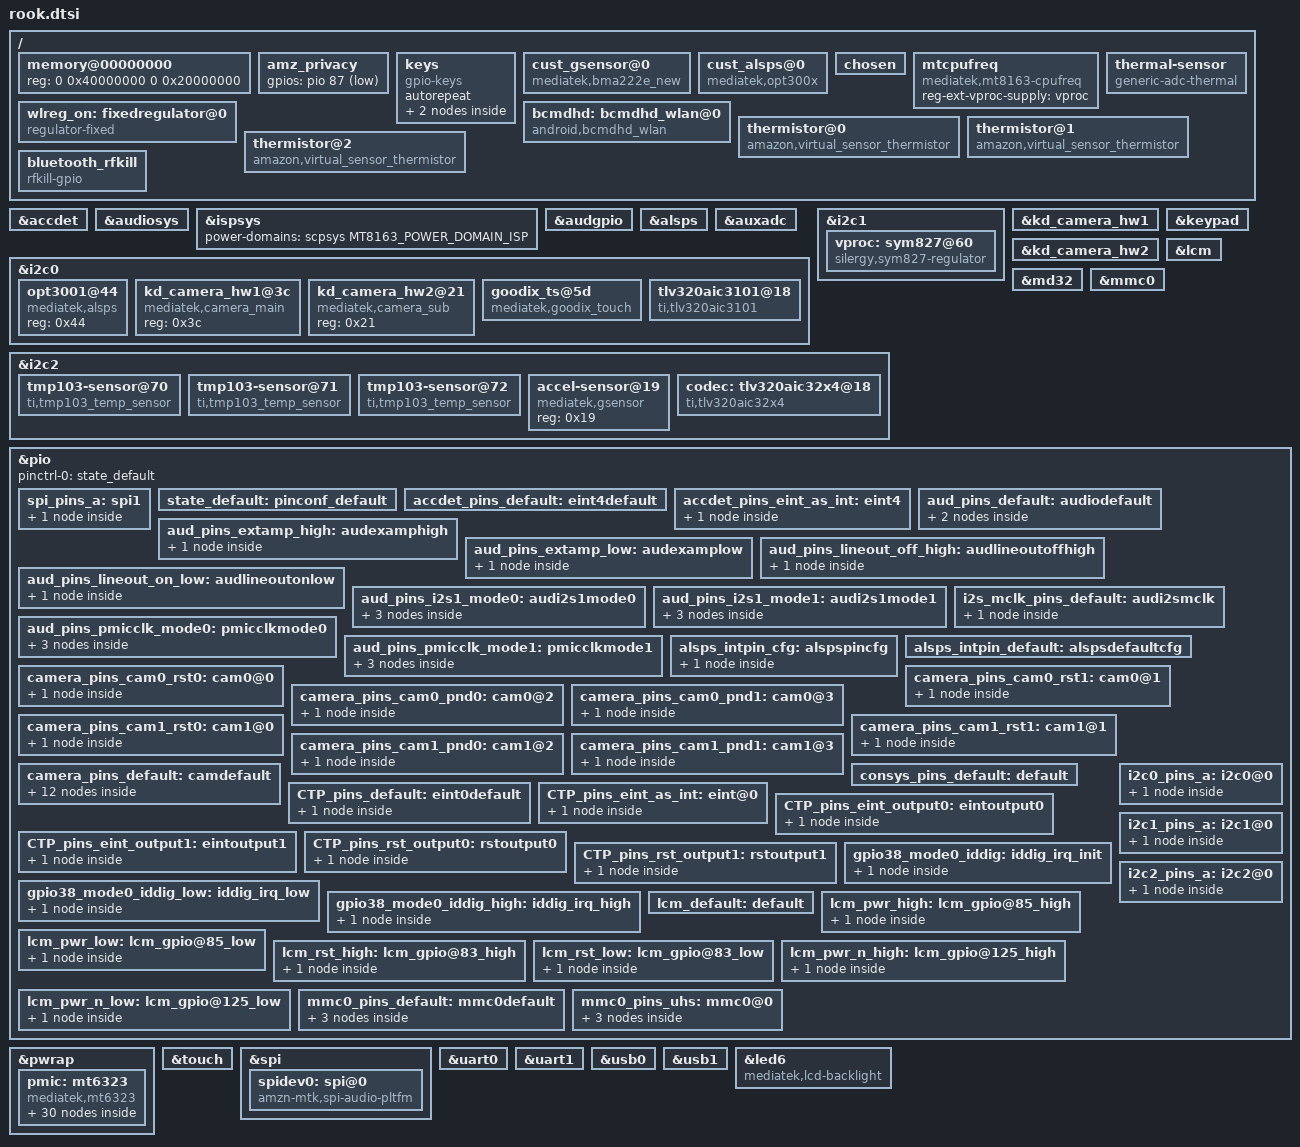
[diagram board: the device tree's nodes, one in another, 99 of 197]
/*
 * Copyright 2011-2017 Amazon.com, Inc. or its affiliates. All Rights Reserved.
 */

#include "mt8163.dtsi"

/ {
	memory@00000000 {
		device_type = "memory";
		reg = <0 0x40000000 0 0x20000000>;
	};

	amz_privacy {
		gpios = <&pio 87 1>;
	};

	keys {
		compatible = "gpio-keys";
		autorepeat;
		vol_up: volumeup@115 {
			label = "Volume Up Key";
			linux,code = <115>;
			gpios = <&pio 37 1>;
			debounce-interval = <20>;
		};
		vol_dn: volumedn@114 {
			label = "Volume Down Key";
			linux,code = <114>;
			gpios = <&pio 50 1>;
			debounce-interval = <20>;
		};
	};

	/* Accel Sensor */
	cust_gsensor@0 {
		compatible = "mediatek,bma222e_new";
		i2c_num = <2>;
		i2c_addr = <0x19>;
		direction = <0>;
		power_id = <0xffff>;
		power_vol = <0>;
		firlen = <0>;
		is_batch_supported = <0>;
	};

	cust_alsps@0 {
		compatible              = "mediatek,opt300x";
		i2c_num                 = <0>;
		i2c_addr                = <0x44>;
		polling_mode_als        = <1>;
		power_id                = <0xffff>;
		power_vol               = <0>;
		/* Total has 15 level*/
		als_level       = <0 257 637 1027 2297 5588 6730 11301 20449 25768 31122 45552 57937 57937 57937>;
		/*  Total has 16 range*/
		als_value       = <0 132 304 502 1004 2003 3006 5006 8004 10000 12000 16000 20000 20000 20000 20000>;
		is_batch_supported_ps   = <1>;
	};


	/* chosen */
	chosen {
		bootargs = "console=ttyMT0,921600n1 root=/dev/ram initrd=0x44000200,0x200000";
	};

	mtcpufreq {
		compatible = "mediatek,mt8163-cpufreq";
		reg-ext-vproc-supply = <&vproc>;
	};

	wlreg_on: fixedregulator@0 {
		compatible = "regulator-fixed";
		regulator-name = "wlreg_on";
		regulator-min-microvolt = <1800000>;
		regulator-max-microvolt = <1800000>;
		gpio = <&pio 27 0>;
		startup-delay-us = <1000>;
		enable-active-high;
	};

	bcmdhd: bcmdhd_wlan@0 {
		compatible = "android,bcmdhd_wlan";
		gpios = <&pio 29 0>;
		wlreg_on-supply = <&wlreg_on>;
	};

	/* auxadc thermistor channel */
	thermal-sensor {
		compatible = "generic-adc-thermal";
		#thermal-sensor-cells = <0>;
		io-channels = <&auxadc 0>, <&auxadc 14>, <&auxadc 15>, <&auxadc 12>;
		io-channel-names = "sensor-channel";
	};

	/* Virtual sensor thermistor */
	thermistor@0 {
		compatible = "amazon,virtual_sensor_thermistor";
		thermal_thermistor,offset = <13000>;
		thermal_thermistor,offset_invert = <1>;
		thermal_thermistor,alpha = <50>;
		thermal_thermistor,weight = <380>;
		aux_channel_num = <0>;
		select_device = <0>;
	};
	thermistor@1 {
		compatible = "amazon,virtual_sensor_thermistor";
		thermal_thermistor,offset = <63500>;
		thermal_thermistor,offset_invert = <1>;
		thermal_thermistor,alpha = <100>;
		thermal_thermistor,weight = <0>;
		aux_channel_num = <1>;
		select_device = <1>;
	};
	thermistor@2 {
		compatible = "amazon,virtual_sensor_thermistor";
		thermal_thermistor,offset = <14000>;
		thermal_thermistor,offset_invert = <1>;
		thermal_thermistor,alpha = <50>;
		thermal_thermistor,weight = <250>;
		aux_channel_num = <2>;
		select_device = <0>;
	};

	bluetooth_rfkill: bluetooth_rfkill {
		compatible = "rfkill-gpio";
		label = "bluetooth";
		radio-type = "bluetooth";
		shutdown-gpios = <&pio 28 0>;
		default-blocked;
	};
};

&accdet {
	interrupt-parent = <&pio>;
	interrupts = <4 IRQ_TYPE_LEVEL_HIGH>;
	eint-debounce = <512000>;
	accdet-gpio = <&pio 26 0>;
	accdet-plugout-debounce = <20000>;
	pinctrl-names = "default", "state_eint_as_int";
	pinctrl-0 = <&accdet_pins_default>;
	pinctrl-1 = <&accdet_pins_eint_as_int>;
	status = "okay";
};

&audiosys {
	/*0:Stereo, 1:MonoLeft, 2:MonoRight*/
	channel-type = <2>;
	/* MCLK Frequency for ADC3101/DAC3203 */
	mclk-frequency = <24576000>;
	interrupt-parent = <&pio>;
	interrupts = <4 IRQ_TYPE_LEVEL_LOW>;
	amp-fault-debounce = <512000>;
	amp-fault-gpio = <&pio 121 0>;
};

&ispsys {
	/* Power domains */
	power-domains = <&scpsys MT8163_POWER_DOMAIN_ISP>;
};

&audgpio {
	pinctrl-names = "default",
			"audpmicclk-mode0",
			"audpmicclk-mode1",
			"audi2s1-mode0",
			"audi2s1-mode1",
			"extamp-pullhigh",
			"extamp-pulllow",
			"i2s-mclk",
			"lineout-off-pullhigh",
			"lineout-on-pulllow";
	pinctrl-0 = <&aud_pins_default>;
	pinctrl-1 = <&aud_pins_pmicclk_mode0>;
	pinctrl-2 = <&aud_pins_pmicclk_mode1>;
	pinctrl-3 = <&aud_pins_i2s1_mode0>;
	pinctrl-4 = <&aud_pins_i2s1_mode1>;
	pinctrl-5 = <&aud_pins_extamp_high>;
	pinctrl-6 = <&aud_pins_extamp_low>;
	pinctrl-7 = <&i2s_mclk_pins_default>;
	pinctrl-8 = <&aud_pins_lineout_off_high>;
	pinctrl-9 = <&aud_pins_lineout_on_low>;

	clocks = <&infracfg CLK_INFRA_AUDIO>,
		 <&topckgen CLK_TOP_AUDIO_SEL>,
		 <&topckgen CLK_TOP_AUD_INTBUS_SEL>,
		 <&topckgen CLK_TOP_AUD_1_SEL>,
		 <&topckgen CLK_TOP_AUD_2_SEL>,
		 <&topckgen CLK_TOP_APLL1>,
		 <&topckgen CLK_TOP_APLL2>,
		 <&audiosys CLK_AUDIO_AFE>,
		 <&audiosys CLK_AUDIO_DAC>,
		 <&audiosys CLK_AUDIO_DAC_PREDIS>,
		 <&audiosys CLK_AUDIO_ADC>,
		 <&audiosys CLK_AUDIO_22M>,
		 <&audiosys CLK_AUDIO_24M>,
		 <&audiosys CLK_AUDIO_I2S>,
		 <&audiosys CLK_AUDIO_APLL_TUNER>,
		 <&audiosys CLK_AUDIO_APLL2_TUNER>,
		 <&clk26m>;

	clock-names = "aud_infra_clk",
		      "top_mux_audio",
		      "top_mux_audio_intbus",
		      "aud_mux1_clk",
		      "aud_mux2_clk",
		      "apll1_clk",
		      "apll2_clk",
		      "aud_afe",
		      "aud_dac",
		      "aud_dac_predis",
		      "aud_adc",
		      "aud_22m",
		      "aud_24m",
		      "aud_i2s",
		      "aud_apll_tnr",
		      "aud_apll2_tnr",
		      "top_clk26m_clk";

	status = "okay";
};

&alsps {
	pinctrl-names = "pin_default", "pin_cfg";
	pinctrl-0 = <&alsps_intpin_default>;
	pinctrl-1 = <&alsps_intpin_cfg>;
	status = "okay";
};

&auxadc {
	status = "okay";
};


&i2c0 {
	clock-frequency = <400000>;
	pinctrl-names = "default";
	pinctrl-0 = <&i2c0_pins_a>;
	status = "okay";
	clock-div = <10>;

	opt3001@44 {
		compatible = "mediatek,alsps";
		reg = <0x44>;
	};

	/* in cust_i2c_projXXX.dtsi ? */
	kd_camera_hw1@3c { /* Fix me to right reg val */
		compatible = "mediatek,camera_main";
		reg = <0x3c>;
	};

	/* in cust_i2c_projXXX.dtsi ? */
	kd_camera_hw2@21 { /* Fix me to right reg val */
		compatible = "mediatek,camera_sub";
		reg = <0x21>;
	};

	goodix_ts@5d {
		compatible = "mediatek,goodix_touch";
		reg = <0x5d>;
		interrupt-parent = <&pio>;
		interrupts = <17 IRQ_TYPE_EDGE_RISING>;
	};

	tlv320aic3101@18 {
		compatible = "ti,tlv320aic3101";
		reg = <0x18>, <0x1a>;
		reg-names = "adc0", "adc1";
		enable-gpio = <&pio 35 0>;
		clocks = <&clk26m>;
		clock-names = "mclk";
	};

};

&i2c1 {
	clock-frequency = <400000>;
	pinctrl-names = "default";
	pinctrl-0 = <&i2c1_pins_a>;
	status = "okay";
	clock-div = <10>;

	vproc: sym827@60 {
		compatible = "silergy,sym827-regulator";
		reg = <0x60>;
		regulator-name = "vproc";
		regulator-min-microvolt = <600000>;
		regulator-max-microvolt = <1387500>;
		regulator-enable-ramp-delay = <400>;
		regulator-ramp-delay = <8333>;
		regulator-always-on;
		vsel-gpio = <&pio 34 0>;
	};
};

&i2c2 {
	clock-frequency = <400000>;
	pinctrl-names = "default";
	pinctrl-0 = <&i2c2_pins_a>;
	status = "okay";
	clock-div = <10>;

	tmp103-sensor@70 {
		compatible = "ti,tmp103_temp_sensor";
		reg = <0x70>;
		tmp103-sensor,offset = <2300>;
		tmp103-sensor,alpha = <10>;
		tmp103-sensor,weight = <0>;
	};
	tmp103-sensor@71 {
		compatible = "ti,tmp103_temp_sensor";
		reg = <0x71>;
		tmp103-sensor,offset = <750>;
		tmp103-sensor,alpha = <10>;
		tmp103-sensor,weight = <0>;
	};
	tmp103-sensor@72 {
		compatible = "ti,tmp103_temp_sensor";
		reg = <0x72>;
		tmp103-sensor,offset = <750>;
		tmp103-sensor,alpha = <10>;
		tmp103-sensor,weight = <0>;
	};

	accel-sensor@19 {
		compatible = "mediatek,gsensor";
		reg = <0x19>;
	};


	codec: tlv320aic32x4@18 {
		compatible = "ti,tlv320aic32x4";
		reg = <0x18>;
		reset-gpios = <&pio 22 0>;
		clocks = <&clk26m>;
		clock-names = "mclk";
	};
};

/* Main Cam */
&kd_camera_hw1 {
	reg-vcama-supply = <&mt6323_vcama_reg>;		/* AVDD */
	reg-vcamd-supply = <&mt6323_vcamd_reg>;		/* DVDD */
	reg-vcamio-supply = <&mt6323_vcamio_reg>;	/* DOVDD */
	reg-vcami2c-supply = <&mt6323_vio18_reg>;	/* I2C */

	pinctrl-names = "default", "cam0_rst0", "cam0_rst1", "cam0_pnd0", "cam0_pnd1",
			"cam1_rst0", "cam1_rst1", "cam1_pnd0", "cam1_pnd1","cam_ldo0_0", "cam_ldo0_1";
	pinctrl-0 = <&camera_pins_default>;
	pinctrl-1 = <&camera_pins_cam0_rst0>;
	pinctrl-2 = <&camera_pins_cam0_rst1>;
	pinctrl-3 = <&camera_pins_cam0_pnd0>;
	pinctrl-4 = <&camera_pins_cam0_pnd1>;
	pinctrl-5 = <&camera_pins_cam1_rst0>;
	pinctrl-6 = <&camera_pins_cam1_rst1>;
	pinctrl-7 = <&camera_pins_cam1_pnd0>;
	pinctrl-8 = <&camera_pins_cam1_pnd1>;
/*
	pinctrl-9 = <&camera_pins_cam_ldo0_0>;
	pinctrl-10 = <&camera_pins_cam_ldo0_1>;
*/
	status = "okay";

};

/* Sub Cam */
/* FIX ME: same power pins as Main ? */
&kd_camera_hw2{
	reg-vcama-supply = <&mt6323_vcama_reg>;		/* AVDD */
	reg-vcamd-supply = <&mt6323_vcamd_reg>;		/* DVDD */
	reg-vcamio-supply = <&mt6323_vcamio_reg>;	/* DOVDD */
	reg-vcami2c-supply = <&mt6323_vio18_reg>;	/* I2C */
};

&keypad {
	mediatek,kpd-key-debounce = <1024>;
	mediatek,kpd-sw-pwrkey = <116>;
	mediatek,kpd-hw-pwrkey = <8>;
	mediatek,kpd-sw-rstkey  = <114>;
	mediatek,kpd-hw-rstkey = <17>;
	mediatek,kpd-use-extend-type = <0>;
	/*HW Keycode [0~71] -> Linux Keycode*/
	mediatek,kpd-hw-map-num = <72>;
	mediatek,kpd-hw-init-map = <138 0 0 0 0 0 0 0 0 0 0 0 0 0 0 0 0 0 0 0 0 0 0 0
			0 0 0 0 0 0 0 0 0 0 0 0 0 0 0 0 0 0 0 0 0 0 0 0
			0 0 0 0 0 0 0 0 0 0 0 0 0 0 0 0 0 0 0 0 0 0 0 0 >;
	mediatek,kpd-pwrkey-eint-gpio = <0>;
	mediatek,kpd-pwkey-gpio-din  = <0>;
	mediatek,kpd-hw-dl-key0 = <0>;
	mediatek,kpd-hw-dl-key1 = <17>;
	mediatek,kpd-hw-dl-key2 = <8>;
	mediatek,kpd-hw-recovery-key = <0>;
	mediatek,kpd-hw-factory-key  = <17>;
	mediatek,kpd-show-hw-keycode = <0>;
};

&lcm {
	pinctrl-names = "default", "lcm_pwr_high", "lcm_pwr_low", "lcm_rst_high", "lcm_rst_low",
			"lcm_pwr_n_high", "lcm_pwr_n_low";
	pinctrl-0 = <&lcm_default>;
	pinctrl-1 = <&lcm_pwr_high>;
	pinctrl-2 = <&lcm_pwr_low>;
	pinctrl-3 = <&lcm_rst_high>;
	pinctrl-4 = <&lcm_rst_low>;
	pinctrl-5 = <&lcm_pwr_n_high>;
	pinctrl-6 = <&lcm_pwr_n_low>;
	lcm-vcn33-supply = <&mt6323_vcn33_wifi_reg>;
	lcm-vmch-supply = <&mt6323_vmch_reg>;
	panelid0-gpio = <&pio 32 0>;
	panelid1-gpio = <&pio 44 0>;
};

&md32 {
	status = "okay";
};

&mmc0 {
	pinctrl-names = "default", "state_uhs";
	pinctrl-0 = <&mmc0_pins_default>;
	pinctrl-1 = <&mmc0_pins_uhs>;
	status = "okay";
	bus-width = <8>;
	mediatek,latch-ck = <1>;
	max-frequency = <200000000>;
	cap-mmc-highspeed;
	mmc-hs200-1_8v;
	cap-mmc-hw-reset;
	vmmc-supply = <&mt6323_vemc3v3_reg>;
	vqmmc-supply = <&mt6323_vio18_reg>;
	non-removable;
};

&pio {
	pinctrl-names = "default";
	pinctrl-0 = <&state_default>;

	spi_pins_a: spi1 {
		spi_pads: pins_spi {
			drive-strength = <MTK_DRIVE_4mA>;
		};
	};

	state_default:pinconf_default {
	};

	accdet_pins_default: eint4default {
	};

	accdet_pins_eint_as_int: eint4 {
		pins_cmd_dat {
			pinmux = <MT8163_PIN_26_EINT4__FUNC_GPIO26>;
			bias-disable;
		};
	};

	aud_pins_default: audiodefault {
		pins1 {
			pinmux = <MT8163_PIN_18_PCM_CLK__FUNC_I2S0_BCK0>,
			<MT8163_PIN_19_PCM_SYNC__FUNC_I2S0_LRCK>,
			<MT8163_PIN_20_PCM_RX__FUNC_I2S0_DI>,
			<MT8163_PIN_21_PCM_TX__FUNC_I2S3_DO>;
		};
		pins_cmd_dat {
			pinmux = <MT8163_PIN_121_MSDC1_CMD__FUNC_GPIO121>;
			bias-pull-up = <MTK_PUPD_SET_R1R0_01>;
			drive-strength = <MTK_DRIVE_2mA>;
			input-enable;
		};
	};

	aud_pins_extamp_high: audexamphigh {
		pins_cmd_dat {
			pinmux = <MT8163_PIN_122_MSDC1_CLK__FUNC_GPIO122>;
			slew-rate = <1>;
			output-high;
		};
	};

	aud_pins_extamp_low: audexamplow {
		pins_cmd_dat {
			pinmux = <MT8163_PIN_122_MSDC1_CLK__FUNC_GPIO122>;
			slew-rate = <1>;
			output-low;
		};
	};

	aud_pins_lineout_off_high: audlineoutoffhigh {
		pins_cmd_dat {
			pinmux = <MT8163_PIN_124_MSDC1_DAT1__FUNC_GPIO124>;
			slew-rate = <1>;
			output-high;
		};
	};

	aud_pins_lineout_on_low: audlineoutonlow {
		pins_cmd_dat {
			pinmux = <MT8163_PIN_124_MSDC1_DAT1__FUNC_GPIO124>;
			slew-rate = <1>;
			output-low;
		};
	};


	aud_pins_i2s1_mode0: audi2s1mode0 {
		pins_cmd0_dat {
			pinmux = <MT8163_PIN_72_I2S_DATA_IN__FUNC_GPIO72>;
		};
		pins_cmd1_dat {
			pinmux = <MT8163_PIN_73_I2S_LRCK__FUNC_GPIO73>;
		};
		pins_cmd2_dat {
			pinmux = <MT8163_PIN_74_I2S_BCK__FUNC_GPIO74>;
		};
	};

	aud_pins_i2s1_mode1: audi2s1mode1 {
		pins_cmd0_dat {
			pinmux = <MT8163_PIN_72_I2S_DATA_IN__FUNC_I2S1_DO>;
			drive-strength = <MTK_DRIVE_8mA>;
		};
		pins_cmd1_dat {
			pinmux = <MT8163_PIN_73_I2S_LRCK__FUNC_I2S1_LRCK>;
			drive-strength = <MTK_DRIVE_8mA>;
		};
		pins_cmd2_dat {
			pinmux = <MT8163_PIN_74_I2S_BCK__FUNC_I2S1_BCK>;
			drive-strength = <MTK_DRIVE_8mA>;
		};
	};

	i2s_mclk_pins_default: audi2smclk {
		pins_i2s3_mck {
			pinmux = <MT8163_PIN_6_PWRAP_SPI0_CSN2__FUNC_I2S2_MCK>;
		};
	};

	aud_pins_pmicclk_mode0: pmicclkmode0 {
		pins_cmd0_dat {
			pinmux = <MT8163_PIN_7_AUD_CLK_MOSI__FUNC_GPIO7>;
		};
		pins_cmd1_dat {
			pinmux = <MT8163_PIN_8_AUD_DAT_MISO__FUNC_GPIO8>;
		};
		pins_cmd2_dat {
			pinmux = <MT8163_PIN_9_AUD_DAT_MOSI__FUNC_GPIO9>;
		};
	};

	aud_pins_pmicclk_mode1: pmicclkmode1 {
		pins_cmd0_dat {
			pinmux = <MT8163_PIN_7_AUD_CLK_MOSI__FUNC_AUD_CLK_MOSI>;
		};
		pins_cmd1_dat {
			pinmux = <MT8163_PIN_8_AUD_DAT_MISO__FUNC_AUD_DAT_MISO>;
		};
		pins_cmd2_dat {
			pinmux = <MT8163_PIN_9_AUD_DAT_MOSI__FUNC_AUD_DAT_MOSI>;
		};
	};

	alsps_intpin_cfg: alspspincfg {
		pins_cmd_dat {
			pinmux = <MT8163_PIN_23_EINT1__FUNC_GPIO23>;
			slew-rate = <0>;
			bias-pull-up = <00>;
		};
	};

	alsps_intpin_default: alspsdefaultcfg {
	};


	/* CAMERA GPIO standardization */
	/* Project Dependency : tb8163m1 */
	camera_pins_cam0_rst0: cam0@0 {
		pins_cmd_dat {
			pinmux = <MT8163_PIN_53_SPI_CS__FUNC_GPIO53>;/*GPIO_CAMERA_CMRST_PIN*/
			slew-rate = <1>; /*direction 0:in, 1:out*/
			output-low;/*direction out used only. output_low or high*/
		};
	};
	camera_pins_cam0_rst1: cam0@1 {
		pins_cmd_dat {
			pinmux = <MT8163_PIN_53_SPI_CS__FUNC_GPIO53>;/*GPIO_CAMERA_CMRST_PIN*/
			slew-rate = <1>;
			output-high;
		};
	};
	camera_pins_cam0_pnd0: cam0@2 {
		pins_cmd_dat {
			pinmux = <MT8163_PIN_56_SPI_MO__FUNC_GPIO56>;/*GPIO_CAMERA_CMPDN_PIN*/
			slew-rate = <1>;
			output-low;
		};
	};
	camera_pins_cam0_pnd1: cam0@3 {
		pins_cmd_dat {
			pinmux = <MT8163_PIN_56_SPI_MO__FUNC_GPIO56>;/*GPIO_CAMERA_CMPDN_PIN*/
			slew-rate = <1>;
			output-high;
		};
	};
	camera_pins_cam1_rst0: cam1@0 {
		pins_cmd_dat {
			pinmux = <MT8163_PIN_55_SPI_MI__FUNC_GPIO55>;/*GPIO_CAMERA_CMRST1_PIN*/
			slew-rate = <1>; /*direction 0:in, 1:out*/
			output-low;/*direction out used only. output_low or high*/
		};
	};
	camera_pins_cam1_rst1: cam1@1 {
		pins_cmd_dat {
			pinmux = <MT8163_PIN_55_SPI_MI__FUNC_GPIO55>;/*GPIO_CAMERA_CMRST1_PIN*/
			slew-rate = <1>;
			output-high;
		};
	};
	camera_pins_cam1_pnd0: cam1@2 {
		pins_cmd_dat {
			pinmux = <MT8163_PIN_90_MSDC2_DAT3__FUNC_GPIO90>;
			/*GPIO_CAMERA_CMPDN1_PIN*/
			slew-rate = <1>;
			output-low;
		};
	};
	camera_pins_cam1_pnd1: cam1@3 {
		pins_cmd_dat {
			pinmux = <MT8163_PIN_90_MSDC2_DAT3__FUNC_GPIO90>;
			/*GPIO_CAMERA_CMPDN1_PIN*/
			slew-rate = <1>;
			output-high;
		};
	};

/*
	camera_pins_cam_ldo0_0: cam@0 {
		pins_cmd_dat {
			pinmux = <PINMUX_GPIO68__FUNC_GPIO68>;
			slew-rate = <1>;
			output-low;
		};
	};
	camera_pins_cam_ldo0_1: cam@1 {
		pins_cmd_dat {
			pinmux = <PINMUX_GPIO68__FUNC_GPIO68>;
			slew-rate = <1>;
			output-high;
		};
	};
*/

	/* Set MCLK Pin default mode */
	camera_pins_default: camdefault {
		pins_cmd0_dat {
			pinmux = <MT8163_PIN_119_CMMCLK__FUNC_CMMCLK>;	/*MCLK*/
		};
		pins_cmd1_dat {
			pinmux = <MT8163_PIN_107_RDN2__FUNC_CMDAT8>;
		};
		pins_cmd2_dat {
			pinmux = <MT8163_PIN_108_RDP2__FUNC_CMDAT9>;
		};
		pins_cmd3_dat {
			pinmux = <MT8163_PIN_109_RDN3__FUNC_CMDAT4>;
		};
		pins_cmd4_dat {
			pinmux = <MT8163_PIN_110_RDP3__FUNC_CMDAT5>;
		};
		pins_cmd5_dat {
			pinmux = <MT8163_PIN_111_RCN_A__FUNC_CMDAT6>;
		};
		pins_cmd6_dat {
			pinmux = <MT8163_PIN_112_RCP_A__FUNC_CMDAT7>;
		};
		pins_cmd7_dat {
			pinmux = <MT8163_PIN_113_RDN1_A__FUNC_CMDAT2>;
		};
		pins_cmd8_dat {
			pinmux = <MT8163_PIN_114_RDP1_A__FUNC_CMDAT3>;
		};
		pins_cmd9_dat {
			pinmux = <MT8163_PIN_115_RDN0_A__FUNC_CMHSYNC>;
		};
		pins_cmd10_dat {
			pinmux = <MT8163_PIN_116_RDP0_A__FUNC_CMVSYNC>;
		};
		pins_cmd11_dat {
			pinmux = <MT8163_PIN_120_CMPCLK__FUNC_CMPCLK>;
		};
	};

	/* CONSYS GPIO Settings - Start */
	consys_pins_default: default {

	};
	/* CONSYS GPIO Settings - End */

	CTP_pins_default: eint0default {
		pins_cmd_dat {
			pinmux = <MT8163_PIN_49_EINT17__FUNC_GPIO49>;
			slew-rate = <0>;
			bias-disable;
		};
	};

	CTP_pins_eint_as_int: eint@0 {
		pins_cmd_dat {
			pinmux = <MT8163_PIN_49_EINT17__FUNC_GPIO49>;
			slew-rate = <0>;
			bias-pull-up;
		};
	};

	CTP_pins_eint_output0: eintoutput0 {
		pins_cmd_dat {
			pinmux = <MT8163_PIN_49_EINT17__FUNC_GPIO49>;
			slew-rate = <1>;
			output-low;
		};
	};

	CTP_pins_eint_output1: eintoutput1 {
		pins_cmd_dat {
			pinmux = <MT8163_PIN_49_EINT17__FUNC_GPIO49>;
			slew-rate = <1>;
			output-high;
		};
	};

	CTP_pins_rst_output0: rstoutput0 {
		pins_cmd_dat {
			pinmux = <MT8163_PIN_89_MSDC2_DAT2__FUNC_GPIO89>;
			slew-rate = <1>;
			output-low;
		};
	};

	CTP_pins_rst_output1: rstoutput1 {
		pins_cmd_dat {
			pinmux = <MT8163_PIN_89_MSDC2_DAT2__FUNC_GPIO89>;
			slew-rate = <1>;
			output-high;
		};
	};

/* USB GPIO start */
	gpio38_mode0_iddig: iddig_irq_init {
		pins_cmd_dat {
			pinmux = <MT8163_PIN_38_KPCOL2__FUNC_GPIO38>;
			bias-pull-up;
		};
	};

	gpio38_mode0_iddig_low: iddig_irq_low {
		pins_cmd_dat {
			pinmux = <MT8163_PIN_38_KPCOL2__FUNC_GPIO38>;
			bias-pull-down;
		};
	};

	gpio38_mode0_iddig_high: iddig_irq_high {
		pins_cmd_dat {
			pinmux = <MT8163_PIN_38_KPCOL2__FUNC_GPIO38>;
			bias-pull-up;
		};
	};

/* USB GPIO end */

	i2c0_pins_a: i2c0@0 {
		pins1 {
			pinmux = <MT8163_PIN_75_SDA0__FUNC_SDA0_0>,
				 <MT8163_PIN_76_SCL0__FUNC_SCL0_0>;
			bias-disable;
		};
	};

	i2c1_pins_a: i2c1@0 {
		pins1 {
			pinmux = <MT8163_PIN_57_SDA1__FUNC_SDA1_0>,
				 <MT8163_PIN_58_SCL1__FUNC_SCL1_0>;
			bias-disable;
		};
	};

	i2c2_pins_a: i2c2@0 {
		pins1 {
			pinmux = <MT8163_PIN_77_SDA2__FUNC_SDA2_0>,
				 <MT8163_PIN_78_SCL2__FUNC_SCL2_0>;
			bias-disable;
		};
	};

	lcm_default: default {
	};

	lcm_pwr_high: lcm_gpio@85_high {
		pins_cmd_dat {
			pinmux = <MT8163_PIN_85_MSDC2_CMD__FUNC_GPIO85>;
			slew-rate = <1>;
			output-high;
		};
	};

	lcm_pwr_low: lcm_gpio@85_low {
		pins_cmd_dat {
			pinmux = <MT8163_PIN_85_MSDC2_CMD__FUNC_GPIO85>;
			slew-rate = <1>;
			output-low;
		};
	};

	lcm_rst_high: lcm_gpio@83_high {
		pins_cmd_dat {
			pinmux = <MT8163_PIN_83_LCM_RST__FUNC_GPIO83>;
			slew-rate = <1>;
			output-high;
		};
	};

	lcm_rst_low: lcm_gpio@83_low {
		pins_cmd_dat {
			pinmux = <MT8163_PIN_83_LCM_RST__FUNC_GPIO83>;
			slew-rate = <1>;
			output-low;
		};
	};

	lcm_pwr_n_high: lcm_gpio@125_high {
		pins_cmd_dat {
			pinmux = <MT8163_PIN_125_MSDC1_DAT2__FUNC_GPIO125>;
			slew-rate = <1>;
			output-high;
		};
	};

	lcm_pwr_n_low: lcm_gpio@125_low {
		pins_cmd_dat {
			pinmux = <MT8163_PIN_125_MSDC1_DAT2__FUNC_GPIO125>;
			slew-rate = <1>;
			output-low;
		};
	};

	mmc0_pins_default: mmc0default {
		pins_cmd_dat {
			pinmux = <MT8163_PIN_137_MSDC0_DAT0__FUNC_MSDC0_DAT0>,
				<MT8163_PIN_136_MSDC0_DAT1__FUNC_MSDC0_DAT1>,
				<MT8163_PIN_135_MSDC0_DAT2__FUNC_MSDC0_DAT2>,
				<MT8163_PIN_134_MSDC0_DAT3__FUNC_MSDC0_DAT3>,
				<MT8163_PIN_130_MSDC0_DAT4__FUNC_MSDC0_DAT4>,
				<MT8163_PIN_129_MSDC0_DAT5__FUNC_MSDC0_DAT5>,
				<MT8163_PIN_128_MSDC0_DAT6__FUNC_MSDC0_DAT6>,
				<MT8163_PIN_127_MSDC0_DAT7__FUNC_MSDC0_DAT7>,
				<MT8163_PIN_132_MSDC0_CMD__FUNC_MSDC0_CMD>;
			input-enable;
			bias-pull-up;
		};

		pins_clk {
			pinmux = <MT8163_PIN_133_MSDC0_CLK__FUNC_MSDC0_CLK>;
			bias-pull-down;
		};

		pins_rst {
			pinmux = <MT8163_PIN_131_MSDC0_RSTB__FUNC_MSDC0_RSTB>;
			bias-pull-up;
		};
	};

	mmc0_pins_uhs: mmc0@0{
		pins_cmd_dat {
			pinmux = <MT8163_PIN_137_MSDC0_DAT0__FUNC_MSDC0_DAT0>,
				<MT8163_PIN_136_MSDC0_DAT1__FUNC_MSDC0_DAT1>,
				<MT8163_PIN_135_MSDC0_DAT2__FUNC_MSDC0_DAT2>,
				<MT8163_PIN_134_MSDC0_DAT3__FUNC_MSDC0_DAT3>,
				<MT8163_PIN_130_MSDC0_DAT4__FUNC_MSDC0_DAT4>,
				<MT8163_PIN_129_MSDC0_DAT5__FUNC_MSDC0_DAT5>,
				<MT8163_PIN_128_MSDC0_DAT6__FUNC_MSDC0_DAT6>,
				<MT8163_PIN_127_MSDC0_DAT7__FUNC_MSDC0_DAT7>,
				<MT8163_PIN_132_MSDC0_CMD__FUNC_MSDC0_CMD>;
			input-enable;
			drive-strength = <MTK_DRIVE_6mA>;
			bias-pull-up = <MTK_PUPD_SET_R1R0_01>;
		};

		pins_clk {
			pinmux = <MT8163_PIN_133_MSDC0_CLK__FUNC_MSDC0_CLK>;
			drive-strength = <MTK_DRIVE_6mA>;
			bias-pull-down = <MTK_PUPD_SET_R1R0_01>;
		};

		pins_rst {
			pinmux = <MT8163_PIN_131_MSDC0_RSTB__FUNC_MSDC0_RSTB>;
			bias-pull-up;
		};
	};

};

&pwrap {
	pmic: mt6323 {
		compatible = "mediatek,mt6323";

		pmicmt6323: pmicmt6323 {
			compatible = "mediatek,mt6323-pmic";
			interrupt-parent = <&pio>;
			interrupts = <24 IRQ_TYPE_LEVEL_HIGH>;
			/* 20s press to shutdown */
			long-press-shutdown-time = <8>;
		};

		regulators {

			compatible = "mediatek,mt6323-regulator";

			mt6323_vproc_reg: buck_vproc {
				regulator-name = "vproc";
				regulator-min-microvolt = < 700000>;
				regulator-max-microvolt = <1350000>;
				regulator-ramp-delay = <12500>;
				regulator-always-on;
				regulator-boot-on;
			};

			mt6323_vsys_reg: buck_vsys {
				regulator-name = "vsys";
				regulator-min-microvolt = <1400000>;
				regulator-max-microvolt = <2987500>;
				regulator-ramp-delay = <25000>;
				regulator-always-on;
				regulator-boot-on;
			};

			mt6323_vpa_reg: buck_vpa {
				regulator-name = "vpa";
				regulator-min-microvolt = < 500000>;
				regulator-max-microvolt = <3650000>;
			};

			mt6323_vtcxo_reg: ldo_vtcxo {
				regulator-name = "vtcxo";
				regulator-min-microvolt = <2800000>;
				regulator-max-microvolt = <2800000>;
				regulator-enable-ramp-delay = <90>;
				regulator-always-on;
				regulator-boot-on;
			};

			mt6323_vcn28_reg: ldo_vcn28 {
				regulator-name = "vcn28";
				regulator-min-microvolt = <2800000>;
				regulator-max-microvolt = <2800000>;
				regulator-enable-ramp-delay = <185>;
			};

			mt6323_vcn33_bt_reg: ldo_vcn33_bt {
				regulator-name = "vcn33_bt";
				regulator-min-microvolt = <3300000>;
				regulator-max-microvolt = <3600000>;
				regulator-enable-ramp-delay = <185>;
			};

			mt6323_vcn33_wifi_reg: ldo_vcn33_wifi {
				regulator-name = "vcn33_wifi";
				regulator-min-microvolt = <3300000>;
				regulator-max-microvolt = <3600000>;
				regulator-enable-ramp-delay = <185>;
				regulator-always-on;
				regulator-boot-on;
			};

			mt6323_va_reg: ldo_va {
				regulator-name = "va";
				regulator-min-microvolt = <2800000>;
				regulator-max-microvolt = <2800000>;
				regulator-enable-ramp-delay = <216>;
				regulator-always-on;
				regulator-boot-on;
			};

			mt6323_vcama_reg: ldo_vcama {
				regulator-name = "vcama";
				regulator-min-microvolt = <1500000>;
				regulator-max-microvolt = <2800000>;
				regulator-enable-ramp-delay = <216>;
			};

			mt6323_vio28_reg: ldo_vio28 {
				regulator-name = "vio28";
				regulator-min-microvolt = <2800000>;
				regulator-max-microvolt = <2800000>;
				regulator-enable-ramp-delay = <216>;
				regulator-always-on;
				regulator-boot-on;
			};

			mt6323_vusb_reg: ldo_vusb {
				regulator-name = "vusb";
				regulator-min-microvolt = <3300000>;
				regulator-max-microvolt = <3300000>;
				regulator-enable-ramp-delay = <216>;
				regulator-boot-on;
			};

			mt6323_vmc_reg: ldo_vmc {
				regulator-name = "vmc";
				regulator-min-microvolt = <1800000>;
				regulator-max-microvolt = <3300000>;
				regulator-enable-ramp-delay = <36>;
				regulator-boot-on;
			};

			mt6323_vmch_reg: ldo_vmch {
				regulator-name = "vmch";
				regulator-min-microvolt = <3000000>;
				regulator-max-microvolt = <3300000>;
				regulator-enable-ramp-delay = <36>;
				regulator-always-on;
				regulator-boot-on;
			};

			mt6323_vemc3v3_reg: ldo_vemc3v3 {
				regulator-name = "vemc3v3";
				regulator-min-microvolt = <3000000>;
				regulator-max-microvolt = <3300000>;
				regulator-enable-ramp-delay = <36>;
				regulator-boot-on;
			};

			mt6323_vgp1_reg: ldo_vgp1 {
				regulator-name = "vgp1";
				regulator-min-microvolt = <2800000>;
				regulator-max-microvolt = <3300000>;
				regulator-enable-ramp-delay = <216>;
				regulator-always-on;
				regulator-boot-on;
			};

			mt6323_vgp2_reg: ldo_vgp2 {
				regulator-name = "vgp2";
				regulator-min-microvolt = <1200000>;
				regulator-max-microvolt = <1200000>;
				regulator-enable-ramp-delay = <216>;
				regulator-always-on;
				regulator-boot-on;
			};

			mt6323_vgp3_reg: ldo_vgp3 {
				regulator-name = "vgp3";
				regulator-min-microvolt = <1800000>;
				regulator-max-microvolt = <1800000>;
				regulator-enable-ramp-delay = <216>;
			};

			mt6323_vcn18_reg: ldo_vcn18 {
				regulator-name = "vcn18";
				regulator-min-microvolt = <1800000>;
				regulator-max-microvolt = <1800000>;
				regulator-enable-ramp-delay = <216>;
			};

			mt6323_vsim1_reg: ldo_vsim1 {
				regulator-name = "vsim1";
				regulator-min-microvolt = <1800000>;
				regulator-max-microvolt = <3000000>;
				regulator-enable-ramp-delay = <216>;
			};

			mt6323_vsim2_reg: ldo_vsim2 {
				regulator-name = "vsim2";
				regulator-min-microvolt = <1800000>;
				regulator-max-microvolt = <3000000>;
				regulator-enable-ramp-delay = <216>;
			};

			mt6323_vrtc_reg: ldo_vrtc {
				regulator-name = "vrtc";
				regulator-min-microvolt = <2800000>;
				regulator-max-microvolt = <2800000>;
				regulator-always-on;
				regulator-boot-on;
			};

			mt6323_vcamaf_reg: ldo_vcamaf {
				regulator-name = "vcamaf";
				regulator-min-microvolt = <1800000>;
				regulator-max-microvolt = <1800000>;
				regulator-enable-ramp-delay = <216>;
			};

			mt6323_vibr_reg: ldo_vibr {
				regulator-name = "vibr";
				regulator-min-microvolt = <1200000>;
				regulator-max-microvolt = <3300000>;
				regulator-enable-ramp-delay = <36>;
			};

			mt6323_vrf18_reg: ldo_vrf18 {
				regulator-name = "vrf18";
				regulator-min-microvolt = <1825000>;
				regulator-max-microvolt = <1825000>;
				regulator-enable-ramp-delay = <187>;
				regulator-boot-on;
			};

			mt6323_vm_reg: ldo_vm {
				regulator-name = "vm";
				regulator-min-microvolt = <1200000>;
				regulator-max-microvolt = <1800000>;
				regulator-enable-ramp-delay = <216>;
				regulator-always-on;
				regulator-boot-on;
			};

			mt6323_vio18_reg: ldo_vio18 {
				regulator-name = "vio18";
				regulator-min-microvolt = <1800000>;
				regulator-max-microvolt = <1800000>;
				regulator-enable-ramp-delay = <216>;
				regulator-always-on;
				regulator-boot-on;
			};

			mt6323_vcamd_reg: ldo_vcamd {
				regulator-name = "vcamd";
				regulator-min-microvolt = <1200000>;
				regulator-max-microvolt = <1800000>;
				regulator-enable-ramp-delay = <216>;
			};

			mt6323_vcamio_reg: ldo_vcamio {
				regulator-name = "vcamio";
				regulator-min-microvolt = <1800000>;
				regulator-max-microvolt = <1800000>;
				regulator-enable-ramp-delay = <216>;
				regulator-always-on;
				regulator-boot-on;
			};
		};
	};
};

&touch {
	vtouch-supply = <&mt6323_vibr_reg>;
	tpd-resolution = <720 1280>;
	use-tpd-button = <0>;
	tpd-key-num = <4>;
	tpd-key-local= <139 172 158 0>;
	tpd-key-dim-local = <60 850 50 30 180 850 50 30 300 850 50 30 420 850 50 30>;
	tpd-max-touch-num = <5>;
	tpd-filter-enable = <1>;
	tpd-filter-pixel-density = <124>;
	tpd-filter-custom-prameters = <0 0 0 0 0 0 0 0 0 0 0 0>;
	tpd-filter-custom-speed = <0 0 0>;
	pinctrl-names = "default", "state_eint_as_int", "state_eint_output0", "state_eint_output1",
		"state_rst_output0", "state_rst_output1";
	pinctrl-0 = <&CTP_pins_default>;
	pinctrl-1 = <&CTP_pins_eint_as_int>;
	pinctrl-2 = <&CTP_pins_eint_output0>;
	pinctrl-3 = <&CTP_pins_eint_output1>;
	pinctrl-4 = <&CTP_pins_rst_output0>;
	pinctrl-5 = <&CTP_pins_rst_output1>;
	interrupt-gpio = <&pio 49 0>;
	status = "okay";
};


&spi {
	status = "okay";
	spidev0: spi@0 {
		compatible = "amzn-mtk,spi-audio-pltfm";
		reg = <0>;
		spi-max-frequency = <100000000>;
		reg-vcamaf-supply = <&mt6323_vcamaf_reg>; /* FPGA VCCIO2 */
		reg-vcamgp3-supply = <&mt6323_vgp3_reg>; /* FPGA VCCIO0 */
		gpios = <&pio 43 0>;
		pinctrl-names = "default",
				"audpmicclk-mode0",
				"audpmicclk-mode1",
				"audi2s1-mode0",
				"audi2s1-mode1",
				"extamp-pullhigh",
				"extamp-pulllow",
				"i2s-mclk",
				"lineout-off-pullhigh",
				"lineout-on-pulllow";
		pinctrl-0 = <&aud_pins_default>;
		pinctrl-1 = <&aud_pins_pmicclk_mode0>;
		pinctrl-2 = <&aud_pins_pmicclk_mode1>;
		pinctrl-3 = <&aud_pins_i2s1_mode0>;
		pinctrl-4 = <&aud_pins_i2s1_mode1>;
		pinctrl-5 = <&aud_pins_extamp_high>;
		pinctrl-6 = <&aud_pins_extamp_low>;
		pinctrl-7 = <&i2s_mclk_pins_default>;
		pinctrl-8 = <&aud_pins_lineout_off_high>;
		pinctrl-9 = <&aud_pins_lineout_on_low>;
		status = "okay";
	};
};

&uart0 {
	status="okay";
};

&uart1 {
	status="okay";
};

&usb0 {
	vusb-supply = <&mt6323_vusb_reg>;
	pinctrl-names = "iddig_irq_init", "iddig_irq_low", "iddig_irq_high";
	pinctrl-0 = <&gpio38_mode0_iddig>;
	pinctrl-1 = <&gpio38_mode0_iddig_low>;
	pinctrl-2 = <&gpio38_mode0_iddig_high>;
	iddig_gpio = <&pio 38 0>;
	status = "okay";
};

&usb1 {
	status = "okay";
};

&led6 {
	compatible = "mediatek,lcd-backlight";
	led_mode = <5>;
	data = < >;
	pwm_config = <0 0 0 0 0>;
	default_brightness = /bits/ 8 <0x80>;
};

/delete-node/ &led0;
/delete-node/ &led1;
/delete-node/ &led2;
/delete-node/ &led3;
/delete-node/ &led4;
/delete-node/ &led5;
/delete-node/ &mdump_reserved_memory;
